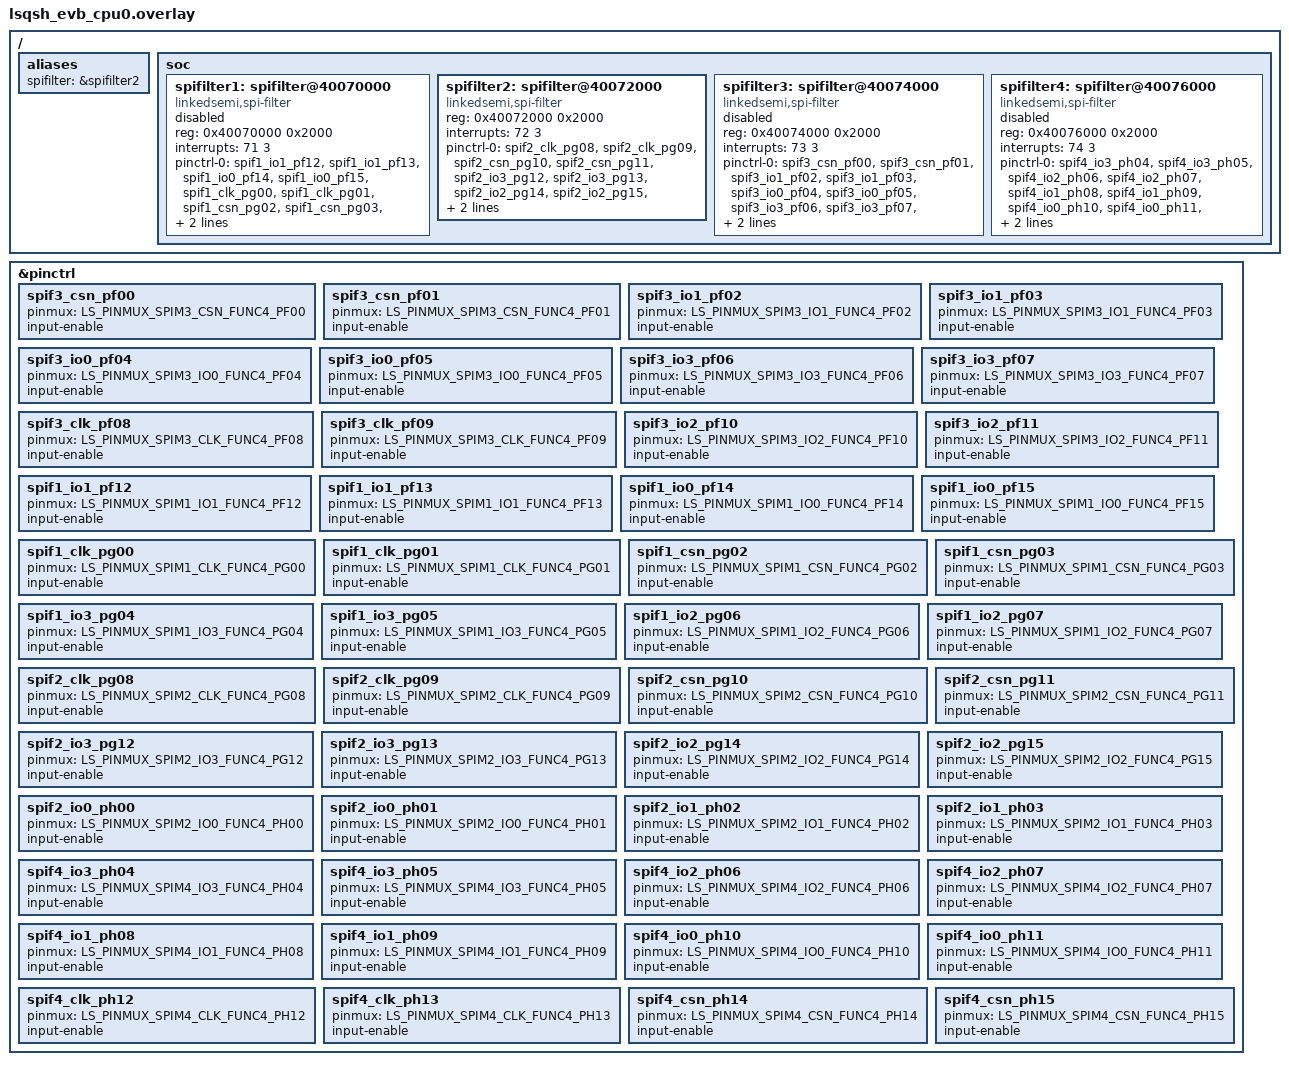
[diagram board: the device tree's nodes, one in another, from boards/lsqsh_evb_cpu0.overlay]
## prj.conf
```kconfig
CONFIG_SPI_FILTER_LINKEDSEMI=y
```

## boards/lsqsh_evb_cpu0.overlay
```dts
#include "../../../include/pfr_tpm_pinctrl.h"
/ {
    aliases {
        spifilter = &spifilter2;
    };

    soc {
        spifilter1: spifilter@40070000 {
            compatible = "linkedsemi,spi-filter";
            reg = <0x40070000 0x2000>;
            interrupts = <71 3>;
            status = "disabled";
        };
        spifilter2: spifilter@40072000 {
            compatible = "linkedsemi,spi-filter";
            reg = <0x40072000 0x2000>;
            interrupts = <72 3>;
            status = "disabled";
        };
        spifilter3: spifilter@40074000 {
            compatible = "linkedsemi,spi-filter";
            reg = <0x40074000 0x2000>;
            interrupts = <73 3>;
            status = "disabled";
        };
        spifilter4: spifilter@40076000 {
            compatible = "linkedsemi,spi-filter";
            reg = <0x40076000 0x2000>;
            interrupts = <74 3>;
            status = "disabled";
        };
    };
};

&pinctrl {
    // /omit-if-no-ref/smbf1_sdao_pb10: smbf1_sdao_pb10 {
    //     pinmux = <LS_PINMUX_SMBF1_SDAO_FUNC3_PB10>;
    //     input-enable;
    // };
    // /omit-if-no-ref/smbf1_sclo_pb11: smbf1_sclo_pb11 {
    //     pinmux = <LS_PINMUX_SMBF1_SCLO_FUNC3_PB11>;
    //     input-enable;
    // };
    // /omit-if-no-ref/smbf2_sdai_pn11: smbf2_sdai_pn11 {
    //     pinmux = <LS_PINMUX_SMBF2_SDAI_FUNC3_PN11>;
    //     input-enable;
    // };
    // /omit-if-no-ref/smbf1_scli_pn12: smbf1_scli_pn12 {
    //     pinmux = <LS_PINMUX_SMBF1_SCLI_FUNC3_PN12>;
    //     input-enable;
    // };
    // /omit-if-no-ref/smbf2_sdao_pn13: smbf2_sdao_pn13 {
    //     pinmux = <LS_PINMUX_SMBF2_SDAO_FUNC3_PN13>;
    //     input-enable;
    // };
    // /omit-if-no-ref/smbf2_sclo_pn14: smbf2_sclo_pn14 {
    //     pinmux = <LS_PINMUX_SMBF2_SCLO_FUNC3_PN14>;
    //     input-enable;
    // };
    // /omit-if-no-ref/smbf2_scli_pn15: smbf2_scli_pn15 {
    //     pinmux = <LS_PINMUX_SMBF2_SCLI_FUNC3_PN15>;
    //     input-enable;
    // };
    // /omit-if-no-ref/smbf1_sdai_pq02: smbf1_sdai_pq02 {
    //     pinmux = <LS_PINMUX_SMBF1_SDAI_FUNC3_PQ02>;
    //     input-enable;
    // };
    // /omit-if-no-ref/smbf4_scli_pq03: smbf4_scli_pq03 {
    //     pinmux = <LS_PINMUX_SMBF4_SCLI_FUNC3_PQ03>;
    //     input-enable;
    // };
    // /omit-if-no-ref/smbf4_sdai_pq04: smbf4_sdai_pq04 {
    //     pinmux = <LS_PINMUX_SMBF4_SDAI_FUNC3_PQ04>;
    //     input-enable;
    // };
    // /omit-if-no-ref/smbf4_sclo_pq05: smbf4_sclo_pq05 {
    //     pinmux = <LS_PINMUX_SMBF4_SCLO_FUNC3_PQ05>;
    //     input-enable;
    // };
    // /omit-if-no-ref/smbf4_sdao_pq06: smbf4_sdao_pq06 {
    //     pinmux = <LS_PINMUX_SMBF4_SDAO_FUNC3_PQ06>;
    //     input-enable;
    // };
    // /omit-if-no-ref/tpm_spis2_csn_pe04: tpm_spis2_csn_pe04 {
    //     pinmux = <LS_PINMUX_TPM_SPIS2_CSN_FUNC4_PE04>;
    //     input-enable;
    // };
    // /omit-if-no-ref/tpm_spis2_sck_pe05: tpm_spis2_sck_pe05 {
    //     pinmux = <LS_PINMUX_TPM_SPIS2_SCK_FUNC4_PE05>;
    //     input-enable;
    // };
    // /omit-if-no-ref/tpm_spis2_mosi_pe06: tpm_spis2_mosi_pe06 {
    //     pinmux = <LS_PINMUX_TPM_SPIS2_MOSI_FUNC4_PE06>;
    //     input-enable;
    // };
    // /omit-if-no-ref/tpm_spis2_miso_pe07: tpm_spis2_miso_pe07 {
    //     pinmux = <LS_PINMUX_TPM_SPIS2_MISO_FUNC4_PE07>;
    //     input-enable;
    // };
    // /omit-if-no-ref/smbf3_sdai_pb12: smbf3_sdai_pb12 {
    //     pinmux = <LS_PINMUX_SMBF3_SDAI_FUNC4_PB12>;
    //     input-enable;
    // };
    // /omit-if-no-ref/smbf3_scli_pb13: smbf3_scli_pb13 {
    //     pinmux = <LS_PINMUX_SMBF3_SCLI_FUNC4_PB13>;
    //     input-enable;
    // };
    // /omit-if-no-ref/smbf3_sdao_pb14: smbf3_sdao_pb14 {
    //     pinmux = <LS_PINMUX_SMBF3_SDAO_FUNC4_PB14>;
    //     input-enable;
    // };
    // /omit-if-no-ref/smbf3_sclo_pb15: smbf3_sclo_pb15 {
    //     pinmux = <LS_PINMUX_SMBF3_SCLO_FUNC4_PB15>;
    //     input-enable;
    // };
    /omit-if-no-ref/spif3_csn_pf00: spif3_csn_pf00 {
        pinmux = <LS_PINMUX_SPIM3_CSN_FUNC4_PF00>;
        input-enable;
    };
    /omit-if-no-ref/spif3_csn_pf01: spif3_csn_pf01 {
        pinmux = <LS_PINMUX_SPIM3_CSN_FUNC4_PF01>;
        input-enable;
    };
    /omit-if-no-ref/spif3_io1_pf02: spif3_io1_pf02 {
        pinmux = <LS_PINMUX_SPIM3_IO1_FUNC4_PF02>;
        input-enable;
    };
    /omit-if-no-ref/spif3_io1_pf03: spif3_io1_pf03 {
        pinmux = <LS_PINMUX_SPIM3_IO1_FUNC4_PF03>;
        input-enable;
    };
    /omit-if-no-ref/spif3_io0_pf04: spif3_io0_pf04 {
        pinmux = <LS_PINMUX_SPIM3_IO0_FUNC4_PF04>;
        input-enable;
    };
    /omit-if-no-ref/spif3_io0_pf05: spif3_io0_pf05 {
        pinmux = <LS_PINMUX_SPIM3_IO0_FUNC4_PF05>;
        input-enable;
    };
    /omit-if-no-ref/spif3_io3_pf06: spif3_io3_pf06 {
        pinmux = <LS_PINMUX_SPIM3_IO3_FUNC4_PF06>;
        input-enable;
    };
    /omit-if-no-ref/spif3_io3_pf07: spif3_io3_pf07 {
        pinmux = <LS_PINMUX_SPIM3_IO3_FUNC4_PF07>;
        input-enable;
    };
    /omit-if-no-ref/spif3_clk_pf08: spif3_clk_pf08 {
        pinmux = <LS_PINMUX_SPIM3_CLK_FUNC4_PF08>;
        input-enable;
    };
    /omit-if-no-ref/spif3_clk_pf09: spif3_clk_pf09 {
        pinmux = <LS_PINMUX_SPIM3_CLK_FUNC4_PF09>;
        input-enable;
    };
    /omit-if-no-ref/spif3_io2_pf10: spif3_io2_pf10 {
        pinmux = <LS_PINMUX_SPIM3_IO2_FUNC4_PF10>;
        input-enable;
    };
    /omit-if-no-ref/spif3_io2_pf11: spif3_io2_pf11 {
        pinmux = <LS_PINMUX_SPIM3_IO2_FUNC4_PF11>;
        input-enable;
    };
    /omit-if-no-ref/spif1_io1_pf12: spif1_io1_pf12 {
        pinmux = <LS_PINMUX_SPIM1_IO1_FUNC4_PF12>;
        input-enable;
    };
    /omit-if-no-ref/spif1_io1_pf13: spif1_io1_pf13 {
        pinmux = <LS_PINMUX_SPIM1_IO1_FUNC4_PF13>;
        input-enable;
    };
    /omit-if-no-ref/spif1_io0_pf14: spif1_io0_pf14 {
        pinmux = <LS_PINMUX_SPIM1_IO0_FUNC4_PF14>;
        input-enable;
    };
    /omit-if-no-ref/spif1_io0_pf15: spif1_io0_pf15 {
        pinmux = <LS_PINMUX_SPIM1_IO0_FUNC4_PF15>;
        input-enable;
    };
    // /omit-if-no-ref/tpm_spis1_mosi_pc00: tpm_spis1_mosi_pc00 {
    //     pinmux = <LS_PINMUX_TPM_SPIS1_MOSI_FUNC4_PC00>;
    //     input-enable;
    // };
    // /omit-if-no-ref/tpm_spis1_miso_pc01: tpm_spis1_miso_pc01 {
    //     pinmux = <LS_PINMUX_TPM_SPIS1_MISO_FUNC4_PC01>;
    //     input-enable;
    // };
    // /omit-if-no-ref/tpm_spis1_csn_pc02: tpm_spis1_csn_pc02 {
    //     pinmux = <LS_PINMUX_TPM_SPIS1_CSN_FUNC4_PC02>;
    //     input-enable;
    // };
    // /omit-if-no-ref/tpm_spis1_sck_pc03: tpm_spis1_sck_pc03 {
    //     pinmux = <LS_PINMUX_TPM_SPIS1_SCK_FUNC4_PC03>;
    //     input-enable;
    // };
    /omit-if-no-ref/spif1_clk_pg00: spif1_clk_pg00 {
        pinmux = <LS_PINMUX_SPIM1_CLK_FUNC4_PG00>;
        input-enable;
    };
    /omit-if-no-ref/spif1_clk_pg01: spif1_clk_pg01 {
        pinmux = <LS_PINMUX_SPIM1_CLK_FUNC4_PG01>;
        input-enable;
    };
    /omit-if-no-ref/spif1_csn_pg02: spif1_csn_pg02 {
        pinmux = <LS_PINMUX_SPIM1_CSN_FUNC4_PG02>;
        input-enable;
    };
    /omit-if-no-ref/spif1_csn_pg03: spif1_csn_pg03 {
        pinmux = <LS_PINMUX_SPIM1_CSN_FUNC4_PG03>;
        input-enable;
    };
    /omit-if-no-ref/spif1_io3_pg04: spif1_io3_pg04 {
        pinmux = <LS_PINMUX_SPIM1_IO3_FUNC4_PG04>;
        input-enable;
    };
    /omit-if-no-ref/spif1_io3_pg05: spif1_io3_pg05 {
        pinmux = <LS_PINMUX_SPIM1_IO3_FUNC4_PG05>;
        input-enable;
    };
    /omit-if-no-ref/spif1_io2_pg06: spif1_io2_pg06 {
        pinmux = <LS_PINMUX_SPIM1_IO2_FUNC4_PG06>;
        input-enable;
    };
    /omit-if-no-ref/spif1_io2_pg07: spif1_io2_pg07 {
        pinmux = <LS_PINMUX_SPIM1_IO2_FUNC4_PG07>;
        input-enable;
    };
    /omit-if-no-ref/spif2_clk_pg08: spif2_clk_pg08 {
        pinmux = <LS_PINMUX_SPIM2_CLK_FUNC4_PG08>;
        input-enable;
    };
    /omit-if-no-ref/spif2_clk_pg09: spif2_clk_pg09 {
        pinmux = <LS_PINMUX_SPIM2_CLK_FUNC4_PG09>;
        input-enable;
    };
    /omit-if-no-ref/spif2_csn_pg10: spif2_csn_pg10 {
        pinmux = <LS_PINMUX_SPIM2_CSN_FUNC4_PG10>;
        input-enable;
    };
    /omit-if-no-ref/spif2_csn_pg11: spif2_csn_pg11 {
        pinmux = <LS_PINMUX_SPIM2_CSN_FUNC4_PG11>;
        input-enable;
    };
    /omit-if-no-ref/spif2_io3_pg12: spif2_io3_pg12 {
        pinmux = <LS_PINMUX_SPIM2_IO3_FUNC4_PG12>;
        input-enable;
    };
    /omit-if-no-ref/spif2_io3_pg13: spif2_io3_pg13 {
        pinmux = <LS_PINMUX_SPIM2_IO3_FUNC4_PG13>;
        input-enable;
    };
    /omit-if-no-ref/spif2_io2_pg14: spif2_io2_pg14 {
        pinmux = <LS_PINMUX_SPIM2_IO2_FUNC4_PG14>;
        input-enable;
    };
    /omit-if-no-ref/spif2_io2_pg15: spif2_io2_pg15 {
        pinmux = <LS_PINMUX_SPIM2_IO2_FUNC4_PG15>;
        input-enable;
    };
    /omit-if-no-ref/spif2_io0_ph00: spif2_io0_ph00 {
        pinmux = <LS_PINMUX_SPIM2_IO0_FUNC4_PH00>;
        input-enable;
    };
    /omit-if-no-ref/spif2_io0_ph01: spif2_io0_ph01 {
        pinmux = <LS_PINMUX_SPIM2_IO0_FUNC4_PH01>;
        input-enable;
    };
    /omit-if-no-ref/spif2_io1_ph02: spif2_io1_ph02 {
        pinmux = <LS_PINMUX_SPIM2_IO1_FUNC4_PH02>;
        input-enable;
    };
    /omit-if-no-ref/spif2_io1_ph03: spif2_io1_ph03 {
        pinmux = <LS_PINMUX_SPIM2_IO1_FUNC4_PH03>;
        input-enable;
    };
    /omit-if-no-ref/spif4_io3_ph04: spif4_io3_ph04 {
        pinmux = <LS_PINMUX_SPIM4_IO3_FUNC4_PH04>;
        input-enable;
    };
    /omit-if-no-ref/spif4_io3_ph05: spif4_io3_ph05 {
        pinmux = <LS_PINMUX_SPIM4_IO3_FUNC4_PH05>;
        input-enable;
    };
    /omit-if-no-ref/spif4_io2_ph06: spif4_io2_ph06 {
        pinmux = <LS_PINMUX_SPIM4_IO2_FUNC4_PH06>;
        input-enable;
    };
    /omit-if-no-ref/spif4_io2_ph07: spif4_io2_ph07 {
        pinmux = <LS_PINMUX_SPIM4_IO2_FUNC4_PH07>;
        input-enable;
    };
    /omit-if-no-ref/spif4_io1_ph08: spif4_io1_ph08 {
        pinmux = <LS_PINMUX_SPIM4_IO1_FUNC4_PH08>;
        input-enable;
    };
    /omit-if-no-ref/spif4_io1_ph09: spif4_io1_ph09 {
        pinmux = <LS_PINMUX_SPIM4_IO1_FUNC4_PH09>;
        input-enable;
    };
    /omit-if-no-ref/spif4_io0_ph10: spif4_io0_ph10 {
        pinmux = <LS_PINMUX_SPIM4_IO0_FUNC4_PH10>;
        input-enable;
    };
    /omit-if-no-ref/spif4_io0_ph11: spif4_io0_ph11 {
        pinmux = <LS_PINMUX_SPIM4_IO0_FUNC4_PH11>;
        input-enable;
    };
    /omit-if-no-ref/spif4_clk_ph12: spif4_clk_ph12 {
        pinmux = <LS_PINMUX_SPIM4_CLK_FUNC4_PH12>;
        input-enable;
    };
    /omit-if-no-ref/spif4_clk_ph13: spif4_clk_ph13 {
        pinmux = <LS_PINMUX_SPIM4_CLK_FUNC4_PH13>;
        input-enable;
    };
    /omit-if-no-ref/spif4_csn_ph14: spif4_csn_ph14 {
        pinmux = <LS_PINMUX_SPIM4_CSN_FUNC4_PH14>;
        input-enable;
    };
    /omit-if-no-ref/spif4_csn_ph15: spif4_csn_ph15 {
        pinmux = <LS_PINMUX_SPIM4_CSN_FUNC4_PH15>;
        input-enable;
    };
};

&spifilter1 {
    pinctrl-0 = <&spif1_io1_pf12
                 &spif1_io1_pf13
                 &spif1_io0_pf14
                 &spif1_io0_pf15
                 &spif1_clk_pg00
                 &spif1_clk_pg01
                 &spif1_csn_pg02
                 &spif1_csn_pg03
                 &spif1_io3_pg04
                 &spif1_io3_pg05
                 &spif1_io2_pg06
                 &spif1_io2_pg07>;
    pinctrl-names = "default";
    status = "disabled";
};

&spifilter2 {
    pinctrl-0 = <&spif2_clk_pg08
                 &spif2_clk_pg09
                 &spif2_csn_pg10
                 &spif2_csn_pg11
                 &spif2_io3_pg12
                 &spif2_io3_pg13
                 &spif2_io2_pg14
                 &spif2_io2_pg15
                 &spif2_io0_ph00
                 &spif2_io0_ph01
                 &spif2_io1_ph02
                 &spif2_io1_ph03>;
    pinctrl-names = "default";
    status = "okay";
};

&spifilter3 {
    pinctrl-0 = <&spif3_csn_pf00
                 &spif3_csn_pf01
                 &spif3_io1_pf02
                 &spif3_io1_pf03
                 &spif3_io0_pf04
                 &spif3_io0_pf05
                 &spif3_io3_pf06
                 &spif3_io3_pf07
                 &spif3_clk_pf08
                 &spif3_clk_pf09
                 &spif3_io2_pf10
                 &spif3_io2_pf11>;
    pinctrl-names = "default";
    status = "disabled";
};

&spifilter4 {
    pinctrl-0 = <&spif4_io3_ph04
                 &spif4_io3_ph05
                 &spif4_io2_ph06
                 &spif4_io2_ph07
                 &spif4_io1_ph08
                 &spif4_io1_ph09
                 &spif4_io0_ph10
                 &spif4_io0_ph11
                 &spif4_clk_ph12
                 &spif4_clk_ph13
                 &spif4_csn_ph14
                 &spif4_csn_ph15>;
    pinctrl-names = "default";
    status = "disabled";
};
```

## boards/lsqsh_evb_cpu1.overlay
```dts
#include "lsqsh_pinctrl_pfr_tpm.dtsi"

/ {
    aliases {
        spif = &spif3;
    };
};

&spif1 {
    status = "okay";
};

&spif2 {
    status = "okay";
};

&spif3 {
    status = "okay";
};

&spif4 {
    status = "okay";
};

&spi3 {
    cs-gpios = <&gpioi 8 GPIO_ACTIVE_LOW>,
                <&gpiog 2 GPIO_ACTIVE_LOW>;
    status = "okay";
};

&spi4 {
    cs-gpios = <&gpioi 0 GPIO_ACTIVE_LOW>,
                <&gpioq 0 GPIO_ACTIVE_LOW>;
    status = "okay";
};

&dmac1 {
    status = "okay";
};
```

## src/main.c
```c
/*
 * Copyright (c) 2024 Linkedsemi
 *
 * SPDX-License-Identifier: Apache-2.0
 */

#if !defined(CONFIG_SPI_FILTER_LINKEDSEMI)
    #error no CONFIG_SPI_FILTER_LINKEDSEMI define
#endif

#include <zephyr/drivers/spi.h>
#include <zephyr/kernel.h>
#include <stdlib.h>
#include <stdio.h>
#include <zephyr/kernel.h>
#include <zephyr/drivers/spi.h>
#include <reg_spi_filter.h>
#include <spi_filter.h>

int main(void)
{
    const struct device *const spifilter = DEVICE_DT_GET(DT_ALIAS(spif));
    linkedsemi_spi_filter_cold_reset(spifilter);
    spif_dump_cmd_table(spifilter);
    spif_dump_rw_addr_privilege_table(spifilter);
    // spif_add_cmd(spifilter, CMD_READ);
    spif_dump_cmd_table(spifilter);
    spif_dump_rw_addr_privilege_table(spifilter);

    int flag = 1;
    while(1) {
        switch (flag) {
        case 0:
            flag++;
            break;
        case 1:
            spif_switch_to_master(spifilter);
            const struct device *spi_dev = spif_spi_dev(spifilter);
            static const uint8_t tx_buffer[] = {0x9f};
            static uint8_t rx_buffer[3];
            const struct spi_config spi_dev_cfg = {
                .operation = SPI_OP_MODE_MASTER | SPI_WORD_SET(8) | SPI_TRANSFER_MSB,
                .frequency = MHZ(1),
                .cs = {
                    .gpio = *(spif_spi_cs(spifilter)),
                },
            };
            static const struct spi_buf tx_buf = {
                .buf = (void *)tx_buffer,
                .len = sizeof(tx_buffer)
            };
            static const struct spi_buf_set tx = {
                .buffers = &tx_buf,
                .count = 1
            };
            static const struct spi_buf rx_buf = {
                .buf = rx_buffer,
                .len = sizeof(rx_buffer),
            };
            static const struct spi_buf_set rx = {
                .buffers = &rx_buf,
                .count = 1
            };
            int ret;

            ret = spi_transceive(spi_dev, &spi_dev_cfg, &tx, &rx);
            if (ret < 0) {
                printk("transfer failed: %d\n", ret);
                return false;
            }

            spif_switch_to_filter(spifilter);

            flag=0;
            break;
        }

        k_msleep(50);
    }

    return 0;
}
```
